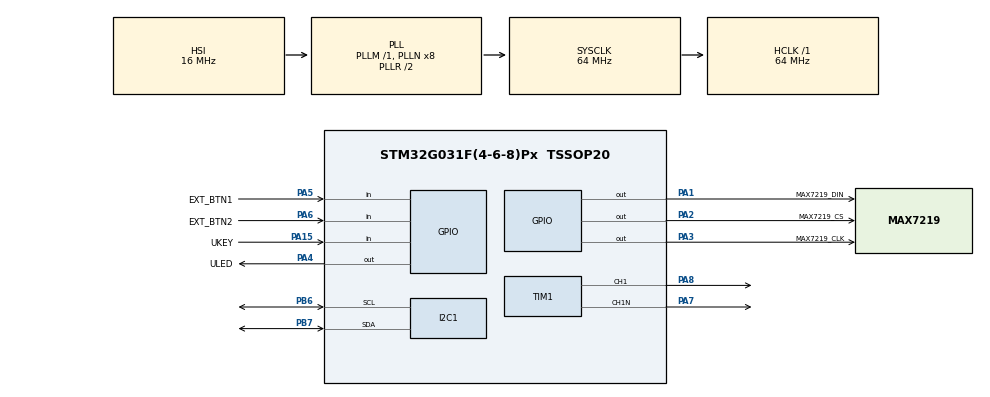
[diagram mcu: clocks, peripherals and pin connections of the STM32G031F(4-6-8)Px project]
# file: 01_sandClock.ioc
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I2C1.Timing=0x10B17DB5
Mcu.Family=STM32G0
Mcu.Name=STM32G031F(4-6-8)Px
Mcu.Package=TSSOP20
PA1.GPIO_Label=MAX7219_DIN
PA1.Signal=GPIO_Output
PA14-BOOT0__PA15.StandardMode=true
PA15.GPIO_Label=UKEY
PA15.GPIO_PuPd=GPIO_PULLDOWN
PA15.Signal=GPIO_Input
PA2.GPIO_Label=MAX7219_CS
PA2.Signal=GPIO_Output
PA3.GPIO_Label=MAX7219_CLK
PA3.Signal=GPIO_Output
PA4.GPIO_Label=ULED
PA4.Signal=GPIO_Output
PA5.GPIO_Label=EXT_BTN1
PA5.GPIO_PuPd=GPIO_PULLUP
PA5.Signal=GPIO_Input
PA6.GPIO_Label=EXT_BTN2
PA6.GPIO_PuPd=GPIO_PULLUP
PA6.Signal=GPIO_Input
PA7.Mode=PWM Generation1 CH1 CH1N
PA7.Signal=TIM1_CH1N
PA8.Signal=S_TIM1_CH1
PB0__PB1__PB2__PA8.StandardMode=true
PB3__PB4__PB5__PB6.StandardMode=true
PB6.Mode=I2C
PB6.Signal=I2C1_SCL
PB7.Mode=I2C
PB7.Signal=I2C1_SDA
PB7__PB8.StandardMode=true
PC14-OSC32_IN\ (PC14).Mode=LSE-External-Oscillator
PC14-OSC32_IN\ (PC14).Signal=RCC_OSC32_IN
PC14-OSC32_IN\ (PC14)__PB9.StandardMode=true
PC15-OSC32_OUT\ (PC15).Mode=LSE-External-Oscillator
PC15-OSC32_OUT\ (PC15).Signal=RCC_OSC32_OUT
ProjectManager.HeapSize=0x200
ProjectManager.StackSize=0x400
ProjectManager.TargetToolchain=STM32CubeIDE
RCC.ADCFreq_Value=64000000
RCC.AHBFreq_Value=64000000
RCC.CortexFreq_Value=64000000
RCC.EXTERNAL_CLOCK_VALUE=12288000
RCC.HCLKFreq_Value=64000000
RCC.HSE_VALUE=8000000
RCC.HSI_VALUE=16000000
RCC.SYSCLKFreq_VALUE=64000000
RCC.SYSCLKSource=RCC_SYSCLKSOURCE_PLLCLK
RCC.VCOOutputFreq_Value=128000000
SH.S_TIM1_CH1.0=TIM1_CH1,PWM Generation1 CH1 CH1N
TIM1.Channel-PWM\ Generation1\ CH1\ CH1N=TIM_CHANNEL_1
VP_TIM1_VS_ClockSourceINT.Mode=Internal
board=custom

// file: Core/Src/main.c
/* USER CODE BEGIN Header */
/**
  ******************************************************************************
  * @file           : main.c
  * @brief          : Main program body
  ******************************************************************************
  * @attention
  *
  * Copyright (c) 2026 STMicroelectronics.
  * All rights reserved.
  *
  * This software is licensed under terms that can be found in the LICENSE file
  * in the root directory of this software component.
  * If no LICENSE file comes with this software, it is provided AS-IS.
  *
  ******************************************************************************
  */
/* USER CODE END Header */
#include "main.h"

/* USER CODE BEGIN Includes */
#include "sand_clock.h"

/* USER CODE END Includes */

I2C_HandleTypeDef hi2c1;

TIM_HandleTypeDef htim1;

void SystemClock_Config(void);
static void MX_GPIO_Init(void);
static void MX_I2C1_Init(void);
static void MX_TIM1_Init(void);

int main(void)
{

  /* MCU Configuration--------------------------------------------------------*/

  /* Reset of all peripherals, Initializes the Flash interface and the Systick. */
  HAL_Init();

  /* Configure the system clock */
  SystemClock_Config();

  /* Initialize all configured peripherals */
  MX_GPIO_Init();
  MX_I2C1_Init();
  MX_TIM1_Init();
  /* USER CODE BEGIN 2 */
  SandClock_Init();

  /* USER CODE END 2 */

  /* Infinite loop */
  while (1)
  {

    /* USER CODE BEGIN 3 */
    SandClock_Tick();
  }
  /* USER CODE END 3 */
}

void SystemClock_Config(void)
{
  RCC_OscInitTypeDef RCC_OscInitStruct = {0};
  RCC_ClkInitTypeDef RCC_ClkInitStruct = {0};

  /** Configure the main internal regulator output voltage
  */
  HAL_PWREx_ControlVoltageScaling(PWR_REGULATOR_VOLTAGE_SCALE1);

  /** Initializes the RCC Oscillators according to the specified parameters
  * in the RCC_OscInitTypeDef structure.
  */
  RCC_OscInitStruct.OscillatorType = RCC_OSCILLATORTYPE_HSI;
  RCC_OscInitStruct.HSIState = RCC_HSI_ON;
  RCC_OscInitStruct.HSIDiv = RCC_HSI_DIV1;
  RCC_OscInitStruct.HSICalibrationValue = RCC_HSICALIBRATION_DEFAULT;
  RCC_OscInitStruct.PLL.PLLState = RCC_PLL_ON;
  RCC_OscInitStruct.PLL.PLLSource = RCC_PLLSOURCE_HSI;
  RCC_OscInitStruct.PLL.PLLM = RCC_PLLM_DIV1;
  RCC_OscInitStruct.PLL.PLLN = 8;
  RCC_OscInitStruct.PLL.PLLP = RCC_PLLP_DIV2;
  RCC_OscInitStruct.PLL.PLLQ = RCC_PLLQ_DIV2;
  RCC_OscInitStruct.PLL.PLLR = RCC_PLLR_DIV2;
  if (HAL_RCC_OscConfig(&RCC_OscInitStruct) != HAL_OK)
  {
    Error_Handler();
  }

  /** Initializes the CPU, AHB and APB buses clocks
  */
  RCC_ClkInitStruct.ClockType = RCC_CLOCKTYPE_HCLK|RCC_CLOCKTYPE_SYSCLK
                              |RCC_CLOCKTYPE_PCLK1;
  RCC_ClkInitStruct.SYSCLKSource = RCC_SYSCLKSOURCE_PLLCLK;
  RCC_ClkInitStruct.AHBCLKDivider = RCC_SYSCLK_DIV1;
  RCC_ClkInitStruct.APB1CLKDivider = RCC_HCLK_DIV1;

  if (HAL_RCC_ClockConfig(&RCC_ClkInitStruct, FLASH_LATENCY_2) != HAL_OK)
  {
    Error_Handler();
  }
}

static void MX_I2C1_Init(void)
{

  hi2c1.Instance = I2C1;
  hi2c1.Init.Timing = 0x10B17DB5;
  hi2c1.Init.OwnAddress1 = 0;
  hi2c1.Init.AddressingMode = I2C_ADDRESSINGMODE_7BIT;
  hi2c1.Init.DualAddressMode = I2C_DUALADDRESS_DISABLE;
  hi2c1.Init.OwnAddress2 = 0;
  hi2c1.Init.OwnAddress2Masks = I2C_OA2_NOMASK;
  hi2c1.Init.GeneralCallMode = I2C_GENERALCALL_DISABLE;
  hi2c1.Init.NoStretchMode = I2C_NOSTRETCH_DISABLE;
  if (HAL_I2C_Init(&hi2c1) != HAL_OK)
  {
    Error_Handler();
  }

  /** Configure Analogue filter
  */
  if (HAL_I2CEx_ConfigAnalogFilter(&hi2c1, I2C_ANALOGFILTER_ENABLE) != HAL_OK)
  {
    Error_Handler();
  }

  /** Configure Digital filter
  */
  if (HAL_I2CEx_ConfigDigitalFilter(&hi2c1, 0) != HAL_OK)
  {
    Error_Handler();
  }

}

static void MX_TIM1_Init(void)
{

  TIM_ClockConfigTypeDef sClockSourceConfig = {0};
  TIM_MasterConfigTypeDef sMasterConfig = {0};
  TIM_OC_InitTypeDef sConfigOC = {0};
  TIM_BreakDeadTimeConfigTypeDef sBreakDeadTimeConfig = {0};

  htim1.Instance = TIM1;
  htim1.Init.Prescaler = 0;
  htim1.Init.CounterMode = TIM_COUNTERMODE_UP;
  htim1.Init.Period = 65535;
  htim1.Init.ClockDivision = TIM_CLOCKDIVISION_DIV1;
  htim1.Init.RepetitionCounter = 0;
  htim1.Init.AutoReloadPreload = TIM_AUTORELOAD_PRELOAD_DISABLE;
  if (HAL_TIM_Base_Init(&htim1) != HAL_OK)
  {
    Error_Handler();
  }
  sClockSourceConfig.ClockSource = TIM_CLOCKSOURCE_INTERNAL;
  if (HAL_TIM_ConfigClockSource(&htim1, &sClockSourceConfig) != HAL_OK)
  {
    Error_Handler();
  }
  if (HAL_TIM_PWM_Init(&htim1) != HAL_OK)
  {
    Error_Handler();
  }
  sMasterConfig.MasterOutputTrigger = TIM_TRGO_RESET;
  sMasterConfig.MasterOutputTrigger2 = TIM_TRGO2_RESET;
  sMasterConfig.MasterSlaveMode = TIM_MASTERSLAVEMODE_DISABLE;
  if (HAL_TIMEx_MasterConfigSynchronization(&htim1, &sMasterConfig) != HAL_OK)
  {
    Error_Handler();
  }
  sConfigOC.OCMode = TIM_OCMODE_PWM1;
  sConfigOC.Pulse = 0;
  sConfigOC.OCPolarity = TIM_OCPOLARITY_HIGH;
  sConfigOC.OCNPolarity = TIM_OCNPOLARITY_HIGH;
  sConfigOC.OCFastMode = TIM_OCFAST_DISABLE;
  sConfigOC.OCIdleState = TIM_OCIDLESTATE_RESET;
  sConfigOC.OCNIdleState = TIM_OCNIDLESTATE_RESET;
  if (HAL_TIM_PWM_ConfigChannel(&htim1, &sConfigOC, TIM_CHANNEL_1) != HAL_OK)
  {
    Error_Handler();
  }
  sBreakDeadTimeConfig.OffStateRunMode = TIM_OSSR_DISABLE;
  sBreakDeadTimeConfig.OffStateIDLEMode = TIM_OSSI_DISABLE;
  sBreakDeadTimeConfig.LockLevel = TIM_LOCKLEVEL_OFF;
  sBreakDeadTimeConfig.DeadTime = 0;
  sBreakDeadTimeConfig.BreakState = TIM_BREAK_DISABLE;
  sBreakDeadTimeConfig.BreakPolarity = TIM_BREAKPOLARITY_HIGH;
  sBreakDeadTimeConfig.BreakFilter = 0;
  sBreakDeadTimeConfig.BreakAFMode = TIM_BREAK_AFMODE_INPUT;
  sBreakDeadTimeConfig.Break2State = TIM_BREAK2_DISABLE;
  sBreakDeadTimeConfig.Break2Polarity = TIM_BREAK2POLARITY_HIGH;
  sBreakDeadTimeConfig.Break2Filter = 0;
  sBreakDeadTimeConfig.Break2AFMode = TIM_BREAK_AFMODE_INPUT;
  sBreakDeadTimeConfig.AutomaticOutput = TIM_AUTOMATICOUTPUT_DISABLE;
  if (HAL_TIMEx_ConfigBreakDeadTime(&htim1, &sBreakDeadTimeConfig) != HAL_OK)
  {
    Error_Handler();
  }
  HAL_TIM_MspPostInit(&htim1);

}

static void MX_GPIO_Init(void)
{
  GPIO_InitTypeDef GPIO_InitStruct = {0};

  /* GPIO Ports Clock Enable */
  __HAL_RCC_GPIOB_CLK_ENABLE();
  __HAL_RCC_GPIOC_CLK_ENABLE();
  __HAL_RCC_GPIOA_CLK_ENABLE();

  /*Configure GPIO pin Output Level */
  HAL_GPIO_WritePin(GPIOA, MAX7219_DIN_Pin|MAX7219_CS_Pin|MAX7219_CLK_Pin|ULED_Pin, GPIO_PIN_RESET);

  /*Configure GPIO pins : MAX7219_DIN_Pin MAX7219_CS_Pin MAX7219_CLK_Pin ULED_Pin */
  GPIO_InitStruct.Pin = MAX7219_DIN_Pin|MAX7219_CS_Pin|MAX7219_CLK_Pin|ULED_Pin;
  GPIO_InitStruct.Mode = GPIO_MODE_OUTPUT_PP;
  GPIO_InitStruct.Pull = GPIO_NOPULL;
  GPIO_InitStruct.Speed = GPIO_SPEED_FREQ_LOW;
  HAL_GPIO_Init(GPIOA, &GPIO_InitStruct);

  /*Configure GPIO pins : EXT_BTN1_Pin EXT_BTN2_Pin */
  GPIO_InitStruct.Pin = EXT_BTN1_Pin|EXT_BTN2_Pin;
  GPIO_InitStruct.Mode = GPIO_MODE_INPUT;
  GPIO_InitStruct.Pull = GPIO_PULLUP;
  HAL_GPIO_Init(GPIOA, &GPIO_InitStruct);

  /*Configure GPIO pin : UKEY_Pin */
  GPIO_InitStruct.Pin = UKEY_Pin;
  GPIO_InitStruct.Mode = GPIO_MODE_INPUT;
  GPIO_InitStruct.Pull = GPIO_PULLDOWN;
  HAL_GPIO_Init(UKEY_GPIO_Port, &GPIO_InitStruct);

}

void Error_Handler(void)
{
  __disable_irq();
  while (1)
  {
  }
}
